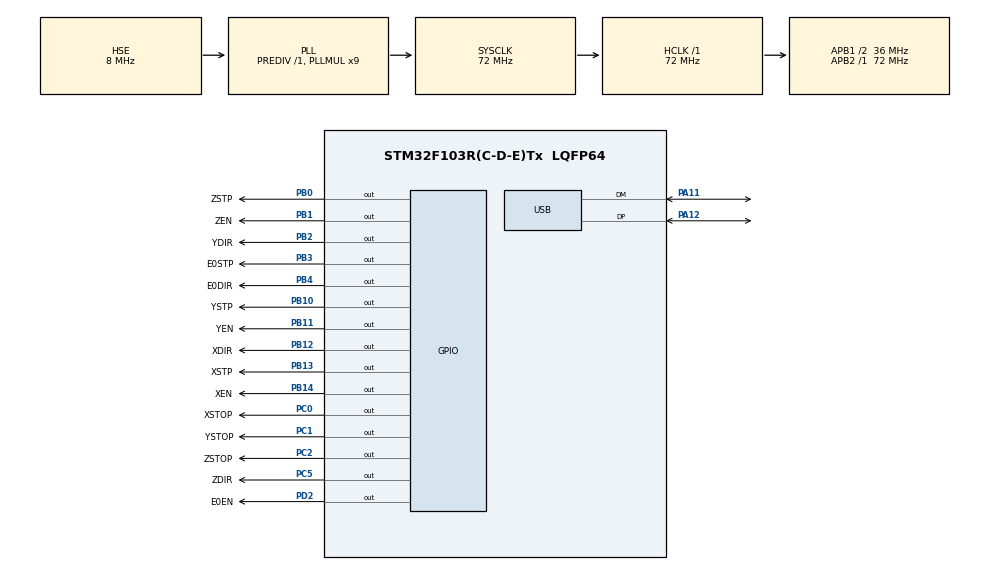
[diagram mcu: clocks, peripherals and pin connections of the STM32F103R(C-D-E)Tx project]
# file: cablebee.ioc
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Mcu.Family=STM32F1
Mcu.Name=STM32F103R(C-D-E)Tx
Mcu.Package=LQFP64
NVIC.PriorityGroup=NVIC_PRIORITYGROUP_4
NVIC.TIM2_IRQn=true\:0\:0\:false\:false\:true\:true\:true
NVIC.USB_LP_CAN1_RX0_IRQn=true\:0\:0\:false\:false\:true\:false\:true
PA10.Signal=USART1_RX
PA11.Mode=Device
PA11.Signal=USB_DM
PA12.Mode=Device
PA12.Signal=USB_DP
PA13.Mode=Serial_Wire
PA13.Signal=SYS_JTMS-SWDIO
PA14.Mode=Serial_Wire
PA14.Signal=SYS_JTCK-SWCLK
PA2.Signal=USART2_TX
PA3.Signal=USART2_RX
PA9.Signal=USART1_TX
PB0.GPIO_Label=ZSTP
PB0.GPIO_Speed=GPIO_SPEED_FREQ_HIGH
PB0.Signal=GPIO_Output
PB1.GPIO_Label=ZEN
PB1.GPIO_Speed=GPIO_SPEED_FREQ_HIGH
PB1.Signal=GPIO_Output
PB10.GPIO_Label=YSTP
PB10.GPIO_Speed=GPIO_SPEED_FREQ_HIGH
PB10.Signal=GPIO_Output
PB11.GPIO_Label=YEN
PB11.GPIO_Speed=GPIO_SPEED_FREQ_HIGH
PB11.Signal=GPIO_Output
PB12.GPIO_Label=XDIR
PB12.GPIO_Speed=GPIO_SPEED_FREQ_HIGH
PB12.Signal=GPIO_Output
PB13.GPIO_Label=XSTP
PB13.GPIO_Speed=GPIO_SPEED_FREQ_HIGH
PB13.Signal=GPIO_Output
PB14.GPIO_Label=XEN
PB14.GPIO_Speed=GPIO_SPEED_FREQ_HIGH
PB14.Signal=GPIO_Output
PB2.GPIO_Label=YDIR
PB2.GPIO_Speed=GPIO_SPEED_FREQ_HIGH
PB2.Signal=GPIO_Output
PB3.GPIO_Label=E0STP
PB3.GPIO_Speed=GPIO_SPEED_FREQ_HIGH
PB3.Signal=GPIO_Output
PB4.GPIO_Label=E0DIR
PB4.GPIO_Speed=GPIO_SPEED_FREQ_HIGH
PB4.Signal=GPIO_Output
PB6.Signal=I2C1_SCL
PB7.Signal=I2C1_SDA
PC0.GPIO_Label=XSTOP
PC0.GPIO_Speed=GPIO_SPEED_FREQ_HIGH
PC0.Signal=GPIO_Output
PC1.GPIO_Label=YSTOP
PC1.GPIO_Speed=GPIO_SPEED_FREQ_HIGH
PC1.Signal=GPIO_Output
PC10.Signal=UART4_TX
PC11.Signal=UART4_RX
PC2.GPIO_Label=ZSTOP
PC2.GPIO_Speed=GPIO_SPEED_FREQ_HIGH
PC2.Signal=GPIO_Output
PC5.GPIO_Label=ZDIR
PC5.GPIO_Speed=GPIO_SPEED_FREQ_HIGH
PC5.Signal=GPIO_Output
PD0-OSC_IN.Mode=HSE-External-Oscillator
PD0-OSC_IN.Signal=RCC_OSC_IN
PD1-OSC_OUT.Mode=HSE-External-Oscillator
PD1-OSC_OUT.Signal=RCC_OSC_OUT
PD2.GPIO_Label=E0EN
PD2.GPIO_Speed=GPIO_SPEED_FREQ_HIGH
PD2.Signal=GPIO_Output
ProjectManager.HeapSize=0x200
ProjectManager.StackSize=0x400
ProjectManager.TargetToolchain=Other Toolchains (GPDSC)
RCC.AHBFreq_Value=72000000
RCC.APB1CLKDivider=RCC_HCLK_DIV2
RCC.APB1Freq_Value=36000000
RCC.APB1TimFreq_Value=72000000
RCC.APB2Freq_Value=72000000
RCC.APB2TimFreq_Value=72000000
RCC.HCLKFreq_Value=72000000
RCC.PLLMUL=RCC_PLL_MUL9
RCC.PLLSourceVirtual=RCC_PLLSOURCE_HSE
RCC.SYSCLKFreq_VALUE=72000000
RCC.SYSCLKSource=RCC_SYSCLKSOURCE_PLLCLK
RCC.USBFreq_Value=48000000
RCC.USBPrescaler=RCC_USBCLKSOURCE_PLL_DIV1_5
TIM2.Channel-Output\ Compare1\ No\ Output=TIM_CHANNEL_1
TIM2.Period=1
TIM2.Prescaler=72-1
USB_DEVICE.CLASS_NAME_FS=CDC
USB_DEVICE.MANUFACTURER_STRING=jason
USB_DEVICE.PRODUCT_STRING_CDC_FS=cableebee VirtualComPort
USB_DEVICE.VirtualMode=Cdc
USB_DEVICE.VirtualModeFS=Cdc_FS
VP_TIM2_VS_no_output1.Mode=Output Compare1 No Output
VP_USB_DEVICE_VS_USB_DEVICE_CDC_FS.Mode=CDC_FS
board=custom

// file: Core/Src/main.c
/* USER CODE BEGIN Header */
/**
  ******************************************************************************
  * @file           : main.c
  * @brief          : Main program body
  ******************************************************************************
  * @attention
  *
  * <h2><center>&copy; Copyright (c) 2021 STMicroelectronics.
  * All rights reserved.</center></h2>
  *
  * This software component is licensed by ST under Ultimate Liberty license
  * SLA0044, the "License"; You may not use this file except in compliance with
  * the License. You may obtain a copy of the License at:
  *                             www.st.com/SLA0044
  *
  ******************************************************************************
  */
/* USER CODE END Header */
#include "main.h"
#include "usb_device.h"

/* USER CODE BEGIN Includes */
// #include <comm.h>
#include <traj_gen.h>
#include <old_main.h>

/* USER CODE END Includes */

TIM_HandleTypeDef htim2;

void SystemClock_Config(void);
static void MX_GPIO_Init(void);
static void MX_TIM2_Init(void);

int main(void)
{

  /* MCU Configuration--------------------------------------------------------*/

  /* Reset of all peripherals, Initializes the Flash interface and the Systick. */
  HAL_Init();

  /* Configure the system clock */
  SystemClock_Config();

  /* Initialize all configured peripherals */
  MX_GPIO_Init();
  MX_TIM2_Init();
  MX_USB_DEVICE_Init();
  /* USER CODE BEGIN 2 */
  HAL_TIM_Base_Start_IT(&htim2);
  old_main();

  /* USER CODE END 2 */

  /* Infinite loop */
  while (1)
  {

  }
}

void SystemClock_Config(void)
{
  RCC_OscInitTypeDef RCC_OscInitStruct = {0};
  RCC_ClkInitTypeDef RCC_ClkInitStruct = {0};
  RCC_PeriphCLKInitTypeDef PeriphClkInit = {0};

  /** Initializes the RCC Oscillators according to the specified parameters
  * in the RCC_OscInitTypeDef structure.
  */
  RCC_OscInitStruct.OscillatorType = RCC_OSCILLATORTYPE_HSE;
  RCC_OscInitStruct.HSEState = RCC_HSE_ON;
  RCC_OscInitStruct.HSEPredivValue = RCC_HSE_PREDIV_DIV1;
  RCC_OscInitStruct.HSIState = RCC_HSI_ON;
  RCC_OscInitStruct.PLL.PLLState = RCC_PLL_ON;
  RCC_OscInitStruct.PLL.PLLSource = RCC_PLLSOURCE_HSE;
  RCC_OscInitStruct.PLL.PLLMUL = RCC_PLL_MUL9;
  if (HAL_RCC_OscConfig(&RCC_OscInitStruct) != HAL_OK)
  {
    Error_Handler();
  }
  /** Initializes the CPU, AHB and APB buses clocks
  */
  RCC_ClkInitStruct.ClockType = RCC_CLOCKTYPE_HCLK | RCC_CLOCKTYPE_SYSCLK | RCC_CLOCKTYPE_PCLK1 | RCC_CLOCKTYPE_PCLK2;
  RCC_ClkInitStruct.SYSCLKSource = RCC_SYSCLKSOURCE_PLLCLK;
  RCC_ClkInitStruct.AHBCLKDivider = RCC_SYSCLK_DIV1;
  RCC_ClkInitStruct.APB1CLKDivider = RCC_HCLK_DIV2;
  RCC_ClkInitStruct.APB2CLKDivider = RCC_HCLK_DIV1;

  if (HAL_RCC_ClockConfig(&RCC_ClkInitStruct, FLASH_LATENCY_2) != HAL_OK)
  {
    Error_Handler();
  }
  PeriphClkInit.PeriphClockSelection = RCC_PERIPHCLK_USB;
  PeriphClkInit.UsbClockSelection = RCC_USBCLKSOURCE_PLL_DIV1_5;
  if (HAL_RCCEx_PeriphCLKConfig(&PeriphClkInit) != HAL_OK)
  {
    Error_Handler();
  }
}

static void MX_TIM2_Init(void)
{

  TIM_MasterConfigTypeDef sMasterConfig = {0};
  TIM_OC_InitTypeDef sConfigOC = {0};

  htim2.Instance = TIM2;
  htim2.Init.Prescaler = 72 - 1;
  htim2.Init.CounterMode = TIM_COUNTERMODE_UP;
  htim2.Init.Period = 1;
  htim2.Init.ClockDivision = TIM_CLOCKDIVISION_DIV1;
  htim2.Init.AutoReloadPreload = TIM_AUTORELOAD_PRELOAD_DISABLE;
  if (HAL_TIM_OC_Init(&htim2) != HAL_OK)
  {
    Error_Handler();
  }
  sMasterConfig.MasterOutputTrigger = TIM_TRGO_RESET;
  sMasterConfig.MasterSlaveMode = TIM_MASTERSLAVEMODE_DISABLE;
  if (HAL_TIMEx_MasterConfigSynchronization(&htim2, &sMasterConfig) != HAL_OK)
  {
    Error_Handler();
  }
  sConfigOC.OCMode = TIM_OCMODE_TIMING;
  sConfigOC.Pulse = 0;
  sConfigOC.OCPolarity = TIM_OCPOLARITY_HIGH;
  sConfigOC.OCFastMode = TIM_OCFAST_DISABLE;
  if (HAL_TIM_OC_ConfigChannel(&htim2, &sConfigOC, TIM_CHANNEL_1) != HAL_OK)
  {
    Error_Handler();
  }
}

static void MX_GPIO_Init(void)
{
  GPIO_InitTypeDef GPIO_InitStruct = {0};

  /* GPIO Ports Clock Enable */
  __HAL_RCC_GPIOD_CLK_ENABLE();
  __HAL_RCC_GPIOC_CLK_ENABLE();
  __HAL_RCC_GPIOA_CLK_ENABLE();
  __HAL_RCC_GPIOB_CLK_ENABLE();

  /*Configure GPIO pin Output Level */
  HAL_GPIO_WritePin(GPIOC, XSTOP_Pin | YSTOP_Pin | ZSTOP_Pin | ZDIR_Pin, GPIO_PIN_RESET);

  /*Configure GPIO pin Output Level */
  HAL_GPIO_WritePin(GPIOB, ZSTP_Pin | ZEN_Pin | YDIR_Pin | YSTP_Pin | YEN_Pin | XDIR_Pin | XSTP_Pin | XEN_Pin | E0STP_Pin | E0DIR_Pin, GPIO_PIN_RESET);

  /*Configure GPIO pin Output Level */
  HAL_GPIO_WritePin(E0EN_GPIO_Port, E0EN_Pin, GPIO_PIN_RESET);

  /*Configure GPIO pins : XSTOP_Pin YSTOP_Pin ZSTOP_Pin ZDIR_Pin */
  GPIO_InitStruct.Pin = XSTOP_Pin | YSTOP_Pin | ZSTOP_Pin | ZDIR_Pin;
  GPIO_InitStruct.Mode = GPIO_MODE_OUTPUT_PP;
  GPIO_InitStruct.Pull = GPIO_NOPULL;
  GPIO_InitStruct.Speed = GPIO_SPEED_FREQ_HIGH;
  HAL_GPIO_Init(GPIOC, &GPIO_InitStruct);

  /*Configure GPIO pins : PA2 PA9 */
  GPIO_InitStruct.Pin = GPIO_PIN_2 | GPIO_PIN_9;
  GPIO_InitStruct.Mode = GPIO_MODE_AF_PP;
  GPIO_InitStruct.Speed = GPIO_SPEED_FREQ_HIGH;
  HAL_GPIO_Init(GPIOA, &GPIO_InitStruct);

  /*Configure GPIO pins : PA3 PA10 */
  GPIO_InitStruct.Pin = GPIO_PIN_3 | GPIO_PIN_10;
  GPIO_InitStruct.Mode = GPIO_MODE_INPUT;
  GPIO_InitStruct.Pull = GPIO_NOPULL;
  HAL_GPIO_Init(GPIOA, &GPIO_InitStruct);

  /*Configure GPIO pins : ZSTP_Pin ZEN_Pin YDIR_Pin YSTP_Pin
                           YEN_Pin XDIR_Pin XSTP_Pin XEN_Pin
                           E0STP_Pin E0DIR_Pin */
  GPIO_InitStruct.Pin = ZSTP_Pin | ZEN_Pin | YDIR_Pin | YSTP_Pin | YEN_Pin | XDIR_Pin | XSTP_Pin | XEN_Pin | E0STP_Pin | E0DIR_Pin;
  GPIO_InitStruct.Mode = GPIO_MODE_OUTPUT_PP;
  GPIO_InitStruct.Pull = GPIO_NOPULL;
  GPIO_InitStruct.Speed = GPIO_SPEED_FREQ_HIGH;
  HAL_GPIO_Init(GPIOB, &GPIO_InitStruct);

  /*Configure GPIO pin : PC10 */
  GPIO_InitStruct.Pin = GPIO_PIN_10;
  GPIO_InitStruct.Mode = GPIO_MODE_AF_PP;
  GPIO_InitStruct.Speed = GPIO_SPEED_FREQ_HIGH;
  HAL_GPIO_Init(GPIOC, &GPIO_InitStruct);

  /*Configure GPIO pin : PC11 */
  GPIO_InitStruct.Pin = GPIO_PIN_11;
  GPIO_InitStruct.Mode = GPIO_MODE_INPUT;
  GPIO_InitStruct.Pull = GPIO_NOPULL;
  HAL_GPIO_Init(GPIOC, &GPIO_InitStruct);

  /*Configure GPIO pin : E0EN_Pin */
  GPIO_InitStruct.Pin = E0EN_Pin;
  GPIO_InitStruct.Mode = GPIO_MODE_OUTPUT_PP;
  GPIO_InitStruct.Pull = GPIO_NOPULL;
  GPIO_InitStruct.Speed = GPIO_SPEED_FREQ_HIGH;
  HAL_GPIO_Init(E0EN_GPIO_Port, &GPIO_InitStruct);

  /*Configure GPIO pins : PB6 PB7 */
  GPIO_InitStruct.Pin = GPIO_PIN_6 | GPIO_PIN_7;
  GPIO_InitStruct.Mode = GPIO_MODE_AF_OD;
  GPIO_InitStruct.Speed = GPIO_SPEED_FREQ_HIGH;
  HAL_GPIO_Init(GPIOB, &GPIO_InitStruct);
}

void Error_Handler(void)
{
  __disable_irq();
  while (1)
  {
  }
}

/************************ (C) COPYRIGHT STMicroelectronics *****END OF FILE****/
